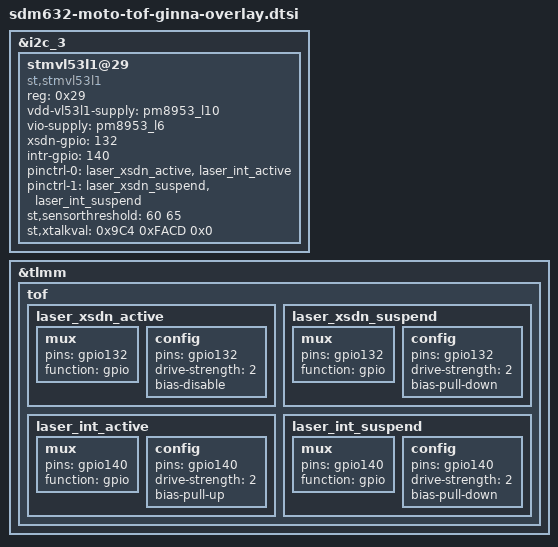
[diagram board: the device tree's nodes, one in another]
/* Copyright (c) 2017, Motorola Mobility Inc. All rights reserved.
 *
 * This program is free software; you can redistribute it and/or modify
 * it under the terms of the GNU General Public License version 2 and
 * only version 2 as published by the Free Software Foundation.
 *
 * This program is distributed in the hope that it will be useful,
 * but WITHOUT ANY WARRANTY; without even the implied warranty of
 * MERCHANTABILITY or FITNESS FOR A PARTICULAR PURPOSE.  See the
 * GNU General Public License for more details.
 */

&i2c_3 { /* BLSP1 QUP3 */
	status = "okay";
	stmvl53l1@29 {
		/* Enable once the matching driver is ported completely */
		status = "ok";
		compatible = "st,stmvl53l1";
		reg = <0x29>;
		vdd-vl53l1-supply = <&pm8953_l10>;
		vio-supply = <&pm8953_l6>;
                xsdn-gpio =  <132>;
                intr-gpio = <140>;
		//gpios = <&tlmm 132 0>, <&tlmm 140 0>;
		//qcom,gpio-reset = <0>;
		//qcom,gpio-req-tbl-num = <0 1>;
		//qcom,gpio-req-tbl-flags = <0 1>;
		//qcom,gpio-req-tbl-label ="TOF_XSHUTDOWN","TOF_INT";
		pinctrl-names = "laser_default", "laser_suspend";
		pinctrl-0 = <&laser_xsdn_active &laser_int_active>;
		pinctrl-1 = <&laser_xsdn_suspend &laser_int_suspend>;
		st,sensorthreshold = <60 65>;
		st,xtalkval = <0x9C4 0xFACD 0x0>;
	};
};

&tlmm {

	tof {

		laser_xsdn_active: laser_xsdn_active {
			mux {
				pins = "gpio132";
				function = "gpio";
			};

			config {
				pins = "gpio132";
				drive-strength = <2>;
				bias-disable;
			};
		};

		laser_xsdn_suspend: laser_xsdn_suspend {
			mux {
				pins = "gpio132";
				function = "gpio";
			};

			config {
				pins = "gpio132";
				drive-strength = <2>;
				bias-pull-down; /* PULL DOWN */
			};
		};

		laser_int_active: laser_int_active {
			mux {
				pins = "gpio140";
				function = "gpio";
			};

			config {
				pins = "gpio140";
				drive-strength = <2>;
				bias-pull-up; /* PULL UP */
			};
		};

		laser_int_suspend: laser_int_suspend {
			mux {
				pins = "gpio140";
				function = "gpio";
			};

			config {
				pins = "gpio140";
				drive-strength = <2>;
				bias-pull-down; /* PULL DOWN */
			};
		};
	};
};
